# STM32WL3R register map
File version: 1.0
CPU: CM0+ r0p0, little endian, MPU, no FPU, 4 interrupt priority bits
Registers are 32-bit, read-write, reset 0x0 unless marked. A register's access mark holds for its fields unless they carry their own. Offsets are from the block's base; [hi:lo] are bit positions.

## RADIO — RADIO_REG_BLOCK address block description
Base 0x49000000
0x00 RF_FSM0_TIMEOUT
  [7:0] ENA_RFREG_TIMER — Timeout for the RF regulator startup (duration in ENA_RF_REG state)
0x04 RF_FSM1_TIMEOUT reset 0x6
  [7:0] SYNTH_SETUP_TIMER — Timeout management for the RF regulator to stabilize after RF PLL power on
0x08 RF_FSM2_TIMEOUT reset 0x50
  [7:0] VCO_CALIB_LOCK_TIMER — Timeout for the RF PLL calibration + RF PLL lock (duration in CALIB_VCO+LOCKRXTX state)
0x0C RF_FSM3_TIMEOUT reset 0x28
  [7:0] VCO_LOCK_TIMER — Timeout for the RF PLL lock event when no calibration is requested (duration in LOCKRXTX state)
0x10 RF_FSM4_TIMEOUT reset 0xF
  [7:0] EN_RX_TIMER — Timeout for the analog RX chain setup (duration in EN_RX state)
0x14 RF_FSM5_TIMEOUT reset 0x19
  [7:0] EN_PA_TIMER — Timeout for the analog PA (DAC) setup (duration in EN_PA state)
0x18 RF_FSM6_TIMEOUT reset 0x19
  [7:0] PA_DWN_ANA_TIMER — Timeout for the analog PA (DAC) ramp down (duration in PA_DWN_ANA state)
0x1C RF_FSM7_TIMEOUT reset 0x5
  [7:0] EN_LNA_TIMER — Timeout for the analog RX chain signals settlement once PGA precharge is shut down (duration in EN_LNA state)
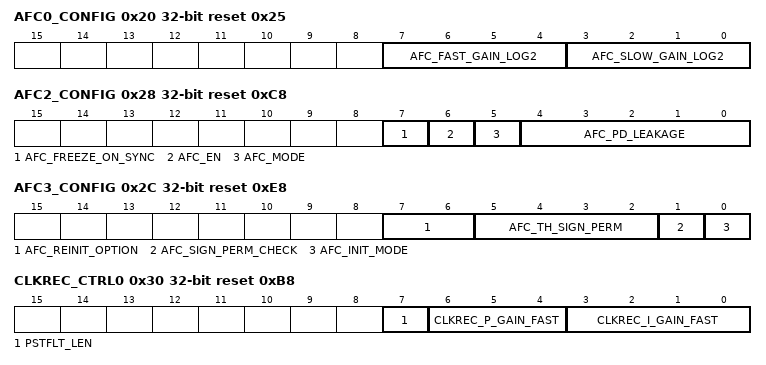
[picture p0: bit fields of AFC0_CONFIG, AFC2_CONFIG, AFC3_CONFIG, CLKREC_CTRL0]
0x20 AFC0_CONFIG reset 0x25
  [7:4] AFC_FAST_GAIN_LOG2 — AFC loop gain in fast mode (2's log)
  [3:0] AFC_SLOW_GAIN_LOG2 — AFC loop gain in slow mode (2's log)
0x24 AFC1_CONFIG reset 0x18
  [7:0] AFC_FAST_PERIOD — Length of the AFC fast period (in number of samples unit)
0x28 AFC2_CONFIG reset 0xC8
  [7] AFC_FREEZE_ON_SYNC — Freeze AFC correction upon SYNC word detection
  [6] AFC_EN — Enable AFC.
  [5] AFC_MODE — Select AFC mode:
  [4:0] AFC_PD_LEAKAGE — AFC Peak Detection leakage.
0x2C AFC3_CONFIG reset 0xE8
  [7:6] AFC_REINIT_OPTION — Select the AFC reinitialization option:
  [5:2] AFC_TH_SIGN_PERM — Threshold of chech sign permanence mechanism.
  [1] AFC_SIGN_PERM_CHECK — Enable the check of sign permanence of AFC corrected signal.
  [0] AFC_INIT_MODE — Control the initialization phase of the AFC and clock recovery algorithms:
0x30 CLKREC_CTRL0 reset 0xB8
  [7] PSTFLT_LEN — Control the length of the demodulator post-filter
  [6:4] CLKREC_P_GAIN_FAST — Clock recovery fast loop gain (log2)
  [3:0] CLKREC_I_GAIN_FAST — Integral fast gain for the clock recovery loop (PLL mode only)
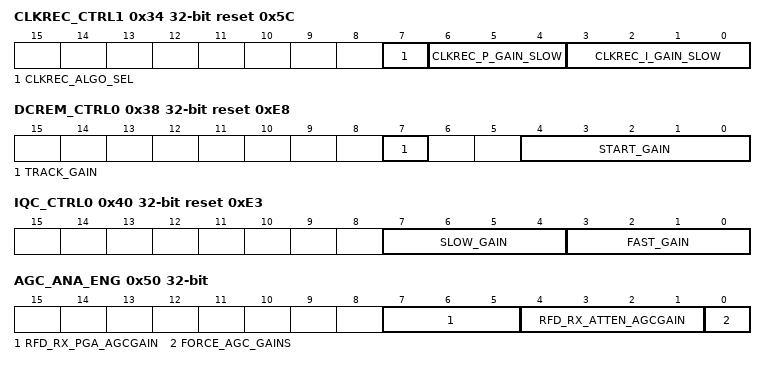
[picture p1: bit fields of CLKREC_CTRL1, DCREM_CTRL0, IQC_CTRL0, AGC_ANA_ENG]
0x34 CLKREC_CTRL1 reset 0x5C
  [7] CLKREC_ALGO_SEL — Symbol timing recovery algorithm selection
  [6:4] CLKREC_P_GAIN_SLOW — Clock recovery slow loop gain (log2)
  [3:0] CLKREC_I_GAIN_SLOW — Integral slow gain for the clock recovery loop (PLL mode only)
0x38 DCREM_CTRL0 reset 0xE8
  [7] TRACK_GAIN — Filter gain in track mode for the DC removal block.
  [4:0] START_GAIN — Filter gain in start mode for the DC removal block.
0x40 IQC_CTRL0 reset 0xE3
  [7:4] SLOW_GAIN — Gain of the correction loop in slow mode.
  [3:0] FAST_GAIN — Gain of the correction loop in fast mode.
0x44 IQC_CTRL1 reset 0x8
  [7:0] QPD_ATTACK — Attack coefficient for QPD:
0x48 IQC_CTRL2 reset 0x8
  [7:0] QPD_DECAY — Decay coefficient for QPD:
0x4C IQC_CTRL3 reset 0x7
  [3:0] FAST_TIME — Duration of the fast mode.
0x50 AGC_ANA_ENG
  [7:5] RFD_RX_PGA_AGCGAIN — Attenuation at PGA level by step of 6dB with binary code:
  [4:1] RFD_RX_ATTEN_AGCGAIN — Attenuation at LNA level by step of 6dB with thermometric code:
  [0] FORCE_AGC_GAINS — Select the mode for AGC analog part:
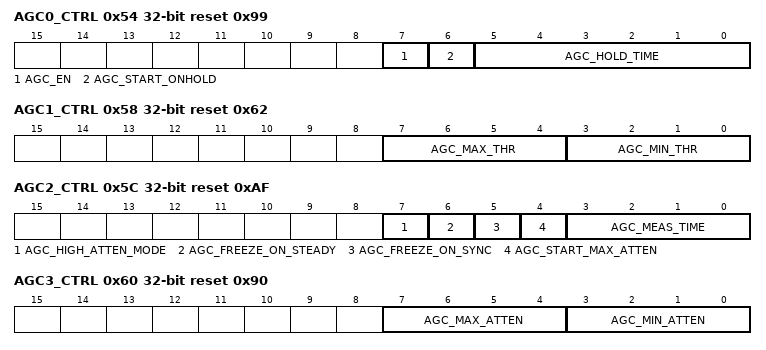
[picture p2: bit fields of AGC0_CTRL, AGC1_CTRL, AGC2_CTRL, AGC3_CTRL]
0x54 AGC0_CTRL reset 0x99
  [7] AGC_EN — Enable the AGC
  [6] AGC_START_ONHOLD — Start the AGC with a hold phase.
  [5:0] AGC_HOLD_TIME
0x58 AGC1_CTRL reset 0x62
  [7:4] AGC_MAX_THR — Maximum signal threshold.
  [3:0] AGC_MIN_THR — Minimum signal threshold.
0x5C AGC2_CTRL reset 0xAF
  [7] AGC_HIGH_ATTEN_MODE — Enable the high attenuation mode.
  [6] AGC_FREEZE_ON_STEADY — Enable the autofreeze feature
  [5] AGC_FREEZE_ON_SYNC — Enable the freeze on SYNC detection feature
  [4] AGC_START_MAX_ATTEN — Start the AGC with maximum attenuation.
  [3:0] AGC_MEAS_TIME — Measure time.
0x60 AGC3_CTRL reset 0x90
  [7:4] AGC_MAX_ATTEN — Maximum AGC attenuation.
  [3:0] AGC_MIN_ATTEN — Minimum AGC attenuation.
0x64 AGC4_CTRL reset 0x2
  [3:0] AGC_FREEZE_THR — Signal threshold for the autofreeze feature.
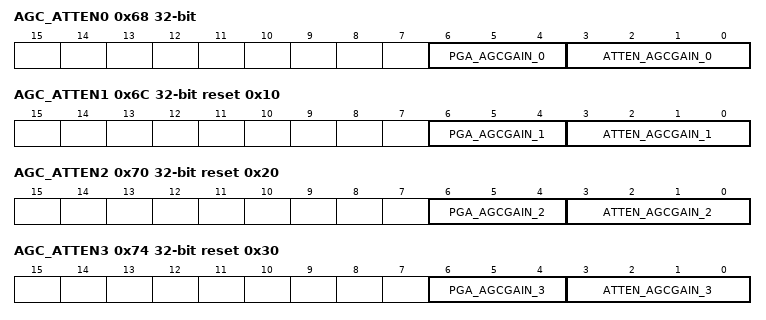
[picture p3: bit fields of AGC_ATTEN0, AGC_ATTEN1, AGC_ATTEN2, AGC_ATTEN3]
0x68 AGC_ATTEN0
  [6:4] PGA_AGCGAIN_0 — AGC attenuation control setting for step 0 on PGA point.
  [3:0] ATTEN_AGCGAIN_0 — AGC attenuation control setting for step 0 for LNA+BOM point.
0x6C AGC_ATTEN1 reset 0x10
  [6:4] PGA_AGCGAIN_1 — AGC attenuation control setting for step 1 on PGA point.
  [3:0] ATTEN_AGCGAIN_1 — AGC attenuation control setting for step 1 for LNA+BOM point.
0x70 AGC_ATTEN2 reset 0x20
  [6:4] PGA_AGCGAIN_2 — AGC attenuation control setting for step 2 on PGA point.
  [3:0] ATTEN_AGCGAIN_2 — AGC attenuation control setting for step 2 for LNA+BOM point.
0x74 AGC_ATTEN3 reset 0x30
  [6:4] PGA_AGCGAIN_3 — AGC attenuation control setting for step 3 on PGA point.
  [3:0] ATTEN_AGCGAIN_3 — AGC attenuation control setting for step 3 for LNA+BOM point.
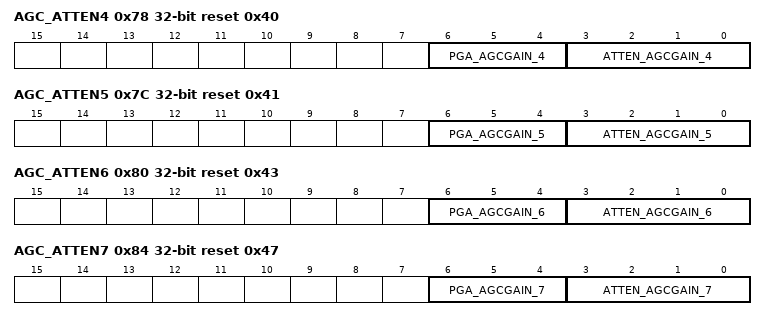
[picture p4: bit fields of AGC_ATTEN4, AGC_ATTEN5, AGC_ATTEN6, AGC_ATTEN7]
0x78 AGC_ATTEN4 reset 0x40
  [6:4] PGA_AGCGAIN_4 — AGC attenuation control setting for step 4 on PGA point.
  [3:0] ATTEN_AGCGAIN_4 — AGC attenuation control setting for step 4 for LNA+BOM point.
0x7C AGC_ATTEN5 reset 0x41
  [6:4] PGA_AGCGAIN_5 — AGC attenuation control setting for step 5 on PGA point.
  [3:0] ATTEN_AGCGAIN_5 — AGC attenuation control setting for step 5 for LNA+BOM point.
0x80 AGC_ATTEN6 reset 0x43
  [6:4] PGA_AGCGAIN_6 — AGC attenuation control setting for step 6 on PGA point.
  [3:0] ATTEN_AGCGAIN_6 — AGC attenuation control setting for step 6 for LNA+BOM point.
0x84 AGC_ATTEN7 reset 0x47
  [6:4] PGA_AGCGAIN_7 — AGC attenuation control setting for step 7 on PGA point.
  [3:0] ATTEN_AGCGAIN_7 — AGC attenuation control setting for step 7 for LNA+BOM point.
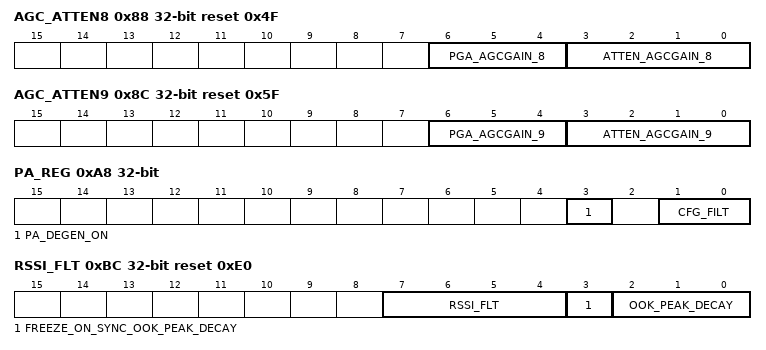
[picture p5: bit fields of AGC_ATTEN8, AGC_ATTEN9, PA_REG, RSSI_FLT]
0x88 AGC_ATTEN8 reset 0x4F
  [6:4] PGA_AGCGAIN_8 — AGC attenuation control setting for step 8 on PGA point.
  [3:0] ATTEN_AGCGAIN_8 — AGC attenuation control setting for step 8 for LNA+BOM point.
0x8C AGC_ATTEN9 reset 0x5F
  [6:4] PGA_AGCGAIN_9 — AGC attenuation control setting for step 9 on PGA point.
  [3:0] ATTEN_AGCGAIN_9 — AGC attenuation control setting for step 9 for LNA+BOM point.
0xA0 AGC_PGA_HWTRIM_OUT ro reset 0x8
  [3:0] AGC_HW_PGA_TRIM — AGC PGA calibration information loaded by HW from the SoC flash.
0xA8 PA_REG
  [3] PA_DEGEN_ON — Enable a 'degeneration' mode, which introduces a pre-distortion to linearize the power control curve.
  [1:0] CFG_FILT — FIR configuration:
0xAC PA_HWTRIM_OUT ro reset 0x88
  [7:4] PA_HW_DEGEN_TRIM — MSB part meaning:
0xBC RSSI_FLT reset 0xE0
  [7:4] RSSI_FLT — Gain of the RSSI filter
  [3] FREEZE_ON_SYNC_OOK_PEAK_DECAY — Freeze on sync OK peak decay
  [2:0] OOK_PEAK_DECAY — Peak decay control for OOK: 3 slow decay; 0 fast decay
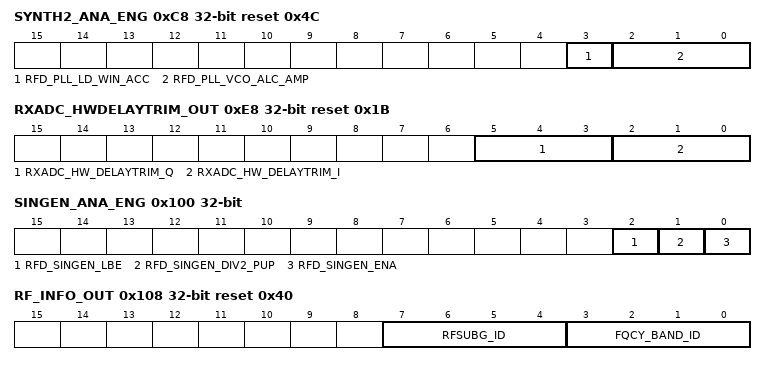
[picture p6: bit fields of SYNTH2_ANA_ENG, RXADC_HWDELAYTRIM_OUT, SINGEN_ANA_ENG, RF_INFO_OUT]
0xC8 SYNTH2_ANA_ENG reset 0x4C
  [3] RFD_PLL_LD_WIN_ACC — Select the PLL lock detector window selection:
  [2:0] RFD_PLL_VCO_ALC_AMP — Select the level of max VCO amplitude in amplitude level control loop.
0xE8 RXADC_HWDELAYTRIM_OUT ro reset 0x1B
  [5:3] RXADC_HW_DELAYTRIM_Q — Control bits of the RX ADC loop delay for Q channel (from SoC Flash).
  [2:0] RXADC_HW_DELAYTRIM_I — Control bits of the RX ADC loop delay for I channel (from SoC Flash).
0xF4 RX_AAF_HWTRIM_OUT ro reset 0x6
  [3:0] AAF_HW_FCTRIM — AAF calibration information loaded by HW.
0x100 SINGEN_ANA_ENG
  [2] RFD_SINGEN_LBE — This bit value is directly connected to the RFSUBG analog IP pin.
  [1] RFD_SINGEN_DIV2_PUP — This bit value is directly connected to the RFSUBG analog IP pin.
  [0] RFD_SINGEN_ENA — Enable SINGEN signal for the RFSUBGanalog IP.
0x108 RF_INFO_OUT ro reset 0x40
  [7:4] RFSUBG_ID — Indicate the version of the analog RFSUBG IP embedded in the device
  [3:0] FQCY_BAND_ID — FQCY_BAND_ID[3:0]: Indicates the version of the RFSUBG IP embedded in the device
0x124 RF_FSM8_TIMEOUT reset 0xA
  [7:0] SYNTH_PDWN_TIMER — Timeout management for the RF regulator to stabilize after PLL shut down
0x128 RF_FSM9_TIMEOUT reset 0x6
  [7:0] END_RX_TIMER — Timeout management for the RF regulator to stabilize after analog RX chain shut down
0x12C RF_FSM10_TIMEOUT reset 0x6
  [7:0] END_TX_TIMER — Timeout management for the RF regulator to stabilize after clock stops on the analog PA block
0x144 SUBG_DIG_CTRL0
  [0] FORCE_GPIO_OUTPUT — Option for the direct GPIO signal output
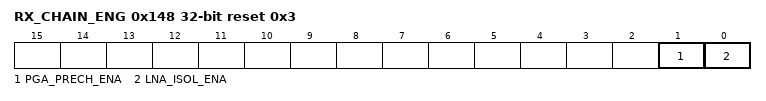
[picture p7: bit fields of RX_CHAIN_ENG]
0x148 RX_CHAIN_ENG reset 0x3
  [1] PGA_PRECH_ENA — Option for PGA precharge during the EN_RX state of the Radio FSM:
  [0] LNA_ISOL_ENA — Option for LNA during the EN_RX state of the Radio FSM:
0x14C DEMOD_DIG_ENG reset 0x3
  [2:0] RX_BLANKING_LENGTH — Number of data samples at RX start for which the signal at the output of the channel filter is kept forced to zero:
